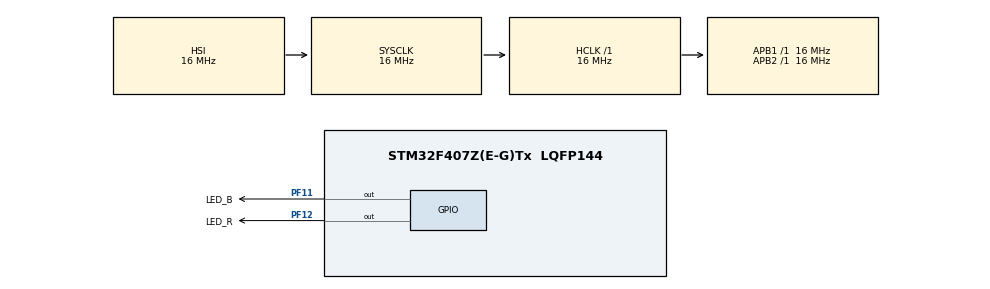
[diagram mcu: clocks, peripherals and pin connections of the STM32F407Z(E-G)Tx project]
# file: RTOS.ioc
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Mcu.Family=STM32F4
Mcu.Name=STM32F407Z(E-G)Tx
Mcu.Package=LQFP144
NVIC.PriorityGroup=NVIC_PRIORITYGROUP_4
NVIC.TIM1_UP_TIM10_IRQn=true\:15\:0\:false\:false\:true\:false\:true\:true
NVIC.TimeBase=TIM1_UP_TIM10_IRQn
NVIC.TimeBaseIP=TIM1
PF11.GPIO_Label=LED_B
PF11.Signal=GPIO_Output
PF12.GPIO_Label=LED_R
PF12.PinState=GPIO_PIN_RESET
PF12.Signal=GPIO_Output
ProjectManager.HeapSize=0x200
ProjectManager.StackSize=0x400
ProjectManager.TargetToolchain=CMake
RCC.AHBFreq_Value=16000000
RCC.APB1Freq_Value=16000000
RCC.APB2Freq_Value=16000000
RCC.CortexFreq_Value=16000000
RCC.HSE_VALUE=25000000
RCC.HSI_VALUE=16000000
RCC.LSE_VALUE=32768
RCC.SYSCLKFreq_VALUE=16000000
RCC.VCOOutputFreq_Value=192000000
VP_SYS_VS_tim1.Mode=TIM1
board=custom

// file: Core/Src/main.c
/* USER CODE BEGIN Header */
/**
  ******************************************************************************
  * @file           : main.c
  * @brief          : Main program body
  ******************************************************************************
  * @attention
  *
  * Copyright (c) 2026 STMicroelectronics.
  * All rights reserved.
  *
  * This software is licensed under terms that can be found in the LICENSE file
  * in the root directory of this software component.
  * If no LICENSE file comes with this software, it is provided AS-IS.
  *
  ******************************************************************************
  */
/* USER CODE END Header */
#include "main.h"
#include "gpio.h"

/* USER CODE BEGIN Includes */
#include "../../RTOS/kernel.h"
/* USER CODE END Includes */

void SystemClock_Config(void);

/* USER CODE BEGIN 0 */
void task1_entry(void)
{
  while (1)
  {
    HAL_GPIO_WritePin(GPIOF, LED_B_Pin|LED_R_Pin, GPIO_PIN_RESET);
  }
}
void task2_entry(void)
{
  while (1)
  {
    HAL_GPIO_WritePin(GPIOF, LED_B_Pin|LED_R_Pin, GPIO_PIN_SET);
  }
}
/* USER CODE END 0 */

int main(void)
{

  /* USER CODE BEGIN 1 */
  TCB task1_tcb;
  TCB task2_tcb;
  static uint32_t task1_stack[STACK_SIZE];
  static uint32_t task2_stack[STACK_SIZE];
  /* USER CODE END 1 */

  /* MCU Configuration--------------------------------------------------------*/

  /* Reset of all peripherals, Initializes the Flash interface and the Systick. */
  HAL_Init();

  /* Configure the system clock */
  SystemClock_Config();

  /* Initialize all configured peripherals */
  MX_GPIO_Init();
  /* USER CODE BEGIN 2 */
  Register(&task1_tcb,&task2_tcb);
  init_statck(&task1_tcb, task1_stack,task1_entry);
  init_statck(&task2_tcb, task2_stack,task2_entry);
  start_scheduler();

  /* USER CODE END 2 */

  /* Infinite loop */
  /* USER CODE BEGIN WHILE */
  while (1)
  {
    //HAL_GPIO_WritePin(GPIOF, LED_B_Pin|LED_R_Pin, GPIO_PIN_SET);
    /* USER CODE END WHILE */

  }
}

void SystemClock_Config(void)
{
  RCC_OscInitTypeDef RCC_OscInitStruct = {0};
  RCC_ClkInitTypeDef RCC_ClkInitStruct = {0};

  /** Configure the main internal regulator output voltage
  */
  __HAL_RCC_PWR_CLK_ENABLE();
  __HAL_PWR_VOLTAGESCALING_CONFIG(PWR_REGULATOR_VOLTAGE_SCALE1);

  /** Initializes the RCC Oscillators according to the specified parameters
  * in the RCC_OscInitTypeDef structure.
  */
  RCC_OscInitStruct.OscillatorType = RCC_OSCILLATORTYPE_HSI;
  RCC_OscInitStruct.HSIState = RCC_HSI_ON;
  RCC_OscInitStruct.HSICalibrationValue = RCC_HSICALIBRATION_DEFAULT;
  RCC_OscInitStruct.PLL.PLLState = RCC_PLL_NONE;
  if (HAL_RCC_OscConfig(&RCC_OscInitStruct) != HAL_OK)
  {
    Error_Handler();
  }

  /** Initializes the CPU, AHB and APB buses clocks
  */
  RCC_ClkInitStruct.ClockType = RCC_CLOCKTYPE_HCLK|RCC_CLOCKTYPE_SYSCLK
                              |RCC_CLOCKTYPE_PCLK1|RCC_CLOCKTYPE_PCLK2;
  RCC_ClkInitStruct.SYSCLKSource = RCC_SYSCLKSOURCE_HSI;
  RCC_ClkInitStruct.AHBCLKDivider = RCC_SYSCLK_DIV1;
  RCC_ClkInitStruct.APB1CLKDivider = RCC_HCLK_DIV1;
  RCC_ClkInitStruct.APB2CLKDivider = RCC_HCLK_DIV1;

  if (HAL_RCC_ClockConfig(&RCC_ClkInitStruct, FLASH_LATENCY_0) != HAL_OK)
  {
    Error_Handler();
  }
}

void HAL_TIM_PeriodElapsedCallback(TIM_HandleTypeDef *htim)
{
  if (htim->Instance == TIM1)
  {
    HAL_IncTick();
  }
}

void Error_Handler(void)
{
  __disable_irq();
  while (1)
  {
  }
}
